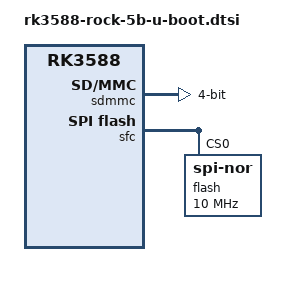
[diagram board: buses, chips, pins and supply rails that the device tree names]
// SPDX-License-Identifier: (GPL-2.0+ OR MIT)
/*
 * Copyright (c) 2023 Collabora Ltd.
 */

#include "rk3588-u-boot.dtsi"

/ {
	aliases {
		mmc1 = &sdmmc;
	};

	chosen {
		u-boot,spl-boot-order = "same-as-spl", &sdmmc, &sdhci;
	};
};

&sdmmc {
	bus-width = <4>;
	status = "okay";
};

&sfc {
	u-boot,dm-spl;
	pinctrl-0 = <&fspim2_pins>;
	pinctrl-names = "default";
	status = "okay";

	flash@0 {
		u-boot,dm-spl;
		compatible = "jedec,spi-nor";
		reg = <0>;
		spi-max-frequency = <10000000>;
		spi-rx-bus-width = <4>;
		spi-tx-bus-width = <1>;
	};
};
